VERSION "1.0 canforge powertrain example"

NS_ :

BS_:

BU_: ECM TCM ABS DASH

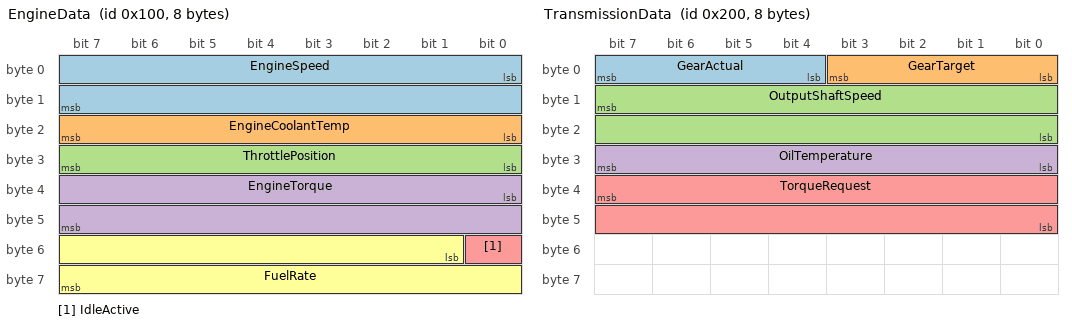
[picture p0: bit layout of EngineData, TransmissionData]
BO_ 256 EngineData: 8 ECM
 SG_ EngineSpeed : 0|16@1+ (0.125,0) [0|8031.875] "rpm" TCM,DASH
 SG_ EngineCoolantTemp : 16|8@1+ (1,-40) [-40|215] "degC" DASH
 SG_ ThrottlePosition : 24|8@1+ (0.4,0) [0|100] "%" TCM
 SG_ EngineTorque : 32|16@1- (0.1,0) [-3276.8|3276.7] "Nm" TCM
 SG_ IdleActive : 48|1@1+ (1,0) [0|1] "" DASH
 SG_ FuelRate : 49|15@1+ (0.05,0) [0|1638.35] "l/h" DASH

BO_ 512 TransmissionData: 8 TCM
 SG_ GearActual : 7|4@0+ (1,0) [0|15] "" DASH,ECM
 SG_ GearTarget : 3|4@0+ (1,0) [0|15] "" DASH
 SG_ OutputShaftSpeed : 15|16@0+ (0.25,0) [0|16383.75] "rpm" ECM
 SG_ OilTemperature : 31|8@0- (1,0) [-128|127] "degC" DASH
 SG_ TorqueRequest : 39|16@0- (0.1,0) [-3276.8|3276.7] "Nm" ECM

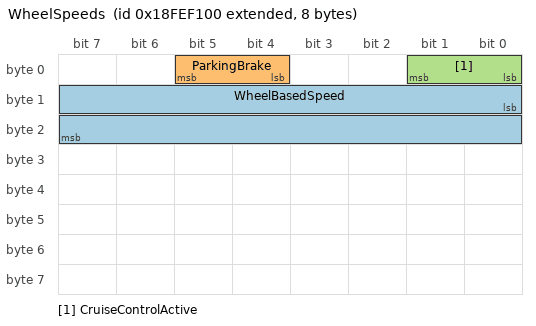
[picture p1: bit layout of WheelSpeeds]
BO_ 2566844672 WheelSpeeds: 8 ABS
 SG_ WheelBasedSpeed : 8|16@1+ (0.00390625,0) [0|250.996] "km/h" DASH,ECM
 SG_ ParkingBrake : 4|2@1+ (1,0) [0|3] "" DASH
 SG_ CruiseControlActive : 0|2@1+ (1,0) [0|3] "" DASH

BO_ 2364539904 EngineControl1: 8 ECM
 SG_ EngineSpeedJ1939 : 24|16@1+ (0.125,0) [0|8031.875] "rpm" TCM
 SG_ DriversDemandTorque : 8|8@1+ (1,-125) [-125|125] "%" TCM

BO_TX_BU_ 512 : TCM,ECM;
CM_ "Small powertrain example database for canforge tests.";
CM_ BU_ ECM "Engine control module";
CM_ BO_ 256 "Cyclic engine data, 10 ms";
CM_ SG_ 256 EngineSpeed "Crankshaft speed";
CM_ SG_ 512 GearActual "Currently engaged gear, 0 = neutral";
BA_DEF_ BO_ "GenMsgCycleTime" INT 0 65535;
BA_DEF_ SG_ "GenSigStartValue" FLOAT -1000000000 1000000000;
BA_DEF_ "BusType" STRING ;
BA_DEF_DEF_ "GenMsgCycleTime" 100;
BA_DEF_DEF_ "GenSigStartValue" 0;
BA_DEF_DEF_ "BusType" "CAN";
BA_ "GenMsgCycleTime" BO_ 256 10;
BA_ "GenMsgCycleTime" BO_ 512 20;
BA_ "GenSigStartValue" SG_ 256 EngineSpeed 800;
VAL_ 512 GearActual 0 "Neutral" 1 "First" 2 "Second" 3 "Third" 4 "Fourth" 5 "Fifth" 6 "Sixth" 15 "Invalid" ;
